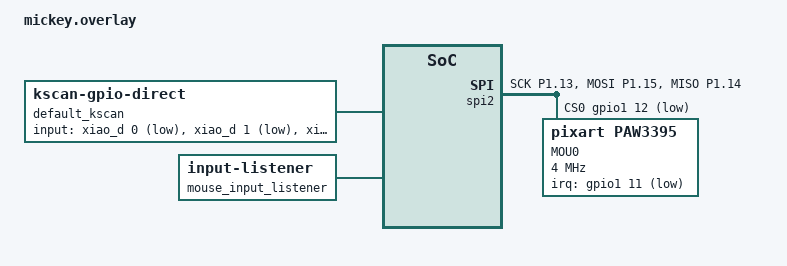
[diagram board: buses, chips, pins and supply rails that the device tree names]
&pinctrl {
	spi2_default: spi2_default {
		group1 {
			psels = <NRF_PSEL(SPIM_SCK, 1, 13)>,
			<NRF_PSEL(SPIM_MOSI, 1, 15)>,
			<NRF_PSEL(SPIM_MISO, 1, 14)>;
		};
	};
	spi2_sleep: spi2_sleep {
		group1 {
			psels = <NRF_PSEL(SPIM_SCK, 1, 13)>,
			<NRF_PSEL(SPIM_MOSI, 1, 15)>,
			<NRF_PSEL(SPIM_MISO, 1, 14)>;
			low-power-enable;
		};
	};
};

#include <zephyr/dt-bindings/input/input-event-codes.h>

&spi2 {
	compatible = "nordic,nrf-spim";
  status = "okay";
	pinctrl-0 = <&spi2_default>;
	pinctrl-1 = <&spi2_sleep>;
	pinctrl-names = "default", "sleep";
	cs-gpios = <&gpio1 12 GPIO_ACTIVE_LOW>;

	pd0: pd@0 {
		compatible = "pixart,paw3395";
	  status = "okay";
		label = "MOU0";
		reg = <0>;
		spi-max-frequency = <4000000>;

		// paw3395 driver parameters
		irq-gpios = <&gpio1 11 (GPIO_ACTIVE_LOW | GPIO_PULL_UP)>;
		cpi = <600>;
		evt-type = <INPUT_EV_REL>;
		x-input-code = <INPUT_REL_X>;
		y-input-code = <INPUT_REL_Y>;
	};
};

/ {
    chosen {
        zmk,kscan = &default_kscan;
    };

    default_kscan: kscan {
        compatible = "zmk,kscan-gpio-direct";
        label = "default_kscan";

        input-gpios =
            <&xiao_d 0 (GPIO_ACTIVE_LOW | GPIO_PULL_UP)>,
            <&xiao_d 1 (GPIO_ACTIVE_LOW | GPIO_PULL_UP)>,
            <&xiao_d 2 (GPIO_ACTIVE_LOW | GPIO_PULL_UP)>,
            <&xiao_d 3 (GPIO_ACTIVE_LOW | GPIO_PULL_UP)>;
    };
	
	
	mouse_input_listener {
		compatible = "zmk,input-listener";
		device = <&pd0>;
	};

};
